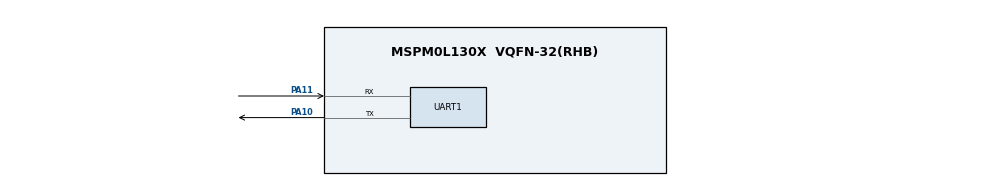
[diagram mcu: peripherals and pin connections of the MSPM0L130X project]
/**
 * These arguments were used when this file was generated. They will be automatically applied on subsequent loads
 * via the GUI or CLI. Run CLI with '--help' for additional information on how to override these arguments.
 * @cliArgs --device "MSPM0L130X" --package "VQFN-32(RHB)" --part "Default" --product "mspm0_sdk@1.20.01.06"
 * @versions {"tool":"1.18.1+3343"}
 */

/**
 * Import the modules used in this configuration.
 */
const Board  = scripting.addModule("/ti/driverlib/Board");
const GPIO   = scripting.addModule("/ti/driverlib/GPIO", {}, false);
const GPIO1  = GPIO.addInstance();
const GPIO2  = GPIO.addInstance();
const GPIO3  = GPIO.addInstance();
const GPIO4  = GPIO.addInstance();
const SYSCTL = scripting.addModule("/ti/driverlib/SYSCTL");
const TIMER  = scripting.addModule("/ti/driverlib/TIMER", {}, false);
const TIMER1 = TIMER.addInstance();
const TIMER2 = TIMER.addInstance();
const UART   = scripting.addModule("/ti/driverlib/UART", {}, false);
const UART1  = UART.addInstance();

/**
 * Write custom configuration values to the imported modules.
 */

GPIO1.$name                          = "GPIO_GRP_0";
GPIO1.associatedPins.create(5);
GPIO1.associatedPins[0].$name        = "CS";
GPIO1.associatedPins[0].assignedPort = "PORTA";
GPIO1.associatedPins[0].initialValue = "SET";
GPIO1.associatedPins[0].ioStructure  = "SD";
GPIO1.associatedPins[0].assignedPin  = "2";
GPIO1.associatedPins[1].$name        = "LED";
GPIO1.associatedPins[1].assignedPort = "PORTA";
GPIO1.associatedPins[1].assignedPin  = "3";
GPIO1.associatedPins[2].assignedPin  = "6";
GPIO1.associatedPins[2].$name        = "D0";
GPIO1.associatedPins[3].$name        = "D1";
GPIO1.associatedPins[3].assignedPin  = "5";
GPIO1.associatedPins[4].$name        = "DC";
GPIO1.associatedPins[4].assignedPin  = "4";

GPIO2.$name                         = "MATRIX";
GPIO2.associatedPins.create(8);
GPIO2.associatedPins[0].$name       = "V1";
GPIO2.associatedPins[0].assignedPin = "13";
GPIO2.associatedPins[1].$name       = "V2";
GPIO2.associatedPins[1].assignedPin = "14";
GPIO2.associatedPins[2].$name       = "V3";
GPIO2.associatedPins[2].assignedPin = "17";
GPIO2.associatedPins[3].$name       = "V4";
GPIO2.associatedPins[3].assignedPin = "18";
GPIO2.associatedPins[4].$name       = "H1";
GPIO2.associatedPins[4].direction   = "INPUT";
GPIO2.associatedPins[4].assignedPin = "0";
GPIO2.associatedPins[4].interruptEn = true;
GPIO2.associatedPins[4].polarity    = "FALL";
GPIO2.associatedPins[5].$name       = "H2";
GPIO2.associatedPins[5].direction   = "INPUT";
GPIO2.associatedPins[5].assignedPin = "1";
GPIO2.associatedPins[5].interruptEn = true;
GPIO2.associatedPins[5].polarity    = "FALL";
GPIO2.associatedPins[6].$name       = "H3";
GPIO2.associatedPins[6].direction   = "INPUT";
GPIO2.associatedPins[6].assignedPin = "7";
GPIO2.associatedPins[6].interruptEn = true;
GPIO2.associatedPins[6].polarity    = "FALL";
GPIO2.associatedPins[7].$name       = "H4";
GPIO2.associatedPins[7].direction   = "INPUT";
GPIO2.associatedPins[7].assignedPin = "12";
GPIO2.associatedPins[7].interruptEn = true;
GPIO2.associatedPins[7].polarity    = "FALL";

GPIO3.$name                          = "BUZZER";
GPIO3.associatedPins.create(2);
GPIO3.associatedPins[0].assignedPin  = "16";
GPIO3.associatedPins[0].$name        = "SDA";
GPIO3.associatedPins[0].initialValue = "SET";
GPIO3.associatedPins[1].assignedPin  = "15";
GPIO3.associatedPins[1].$name        = "SCL";

GPIO4.$name                         = "BLUETOOTH";
GPIO4.associatedPins.create(2);
GPIO4.associatedPins[0].$name       = "TX";
GPIO4.associatedPins[0].assignedPin = "8";
GPIO4.associatedPins[1].$name       = "RX";
GPIO4.associatedPins[1].direction   = "INPUT";
GPIO4.associatedPins[1].assignedPin = "9";

SYSCTL.MFCLKEn = true;

TIMER1.$name             = "TIMER_0";
TIMER1.timerPeriod       = "1 s";
TIMER1.timerClkSrc       = "LFCLK";
TIMER1.timerMode         = "PERIODIC";
TIMER1.interrupts        = ["ZERO"];
TIMER1.interruptPriority = "0";
TIMER1.timerStartTimer   = true;
TIMER1.crossTriggerEn    = true;

TIMER2.$name             = "TIMER_1";
TIMER2.timerClkSrc       = "LFCLK";
TIMER2.timerMode         = "PERIODIC";
TIMER2.interrupts        = ["ZERO"];
TIMER2.interruptPriority = "0";
TIMER2.timerPeriod       = "1 s";
TIMER2.crossTriggerEn    = true;

UART1.$name                    = "UART_0";
UART1.enabledInterrupts        = ["RX","RX_TIMEOUT_ERROR"];
UART1.targetBaudRate           = 115200;
UART1.peripheral.rxPin.$assign = "PA11";
UART1.peripheral.txPin.$assign = "PA10";
UART1.txPinConfig.$name        = "ti_driverlib_gpio_GPIOPinGeneric0";
UART1.rxPinConfig.$name        = "ti_driverlib_gpio_GPIOPinGeneric1";

/**
 * Pinmux solution for unlocked pins/peripherals. This ensures that minor changes to the automatic solver in a future
 * version of the tool will not impact the pinmux you originally saw.  These lines can be completely deleted in order to
 * re-solve from scratch.
 */
Board.peripheral.$suggestSolution            = "DEBUGSS";
Board.peripheral.swclkPin.$suggestSolution   = "PA20";
Board.peripheral.swdioPin.$suggestSolution   = "PA19";
GPIO1.associatedPins[0].pin.$suggestSolution = "PA2";
GPIO1.associatedPins[1].pin.$suggestSolution = "PA3";
GPIO1.associatedPins[2].pin.$suggestSolution = "PA6";
GPIO1.associatedPins[3].pin.$suggestSolution = "PA5";
GPIO1.associatedPins[4].pin.$suggestSolution = "PA4";
GPIO2.associatedPins[0].pin.$suggestSolution = "PA13";
GPIO2.associatedPins[1].pin.$suggestSolution = "PA14";
GPIO2.associatedPins[2].pin.$suggestSolution = "PA17/OPA1.IN0-";
GPIO2.associatedPins[3].pin.$suggestSolution = "PA18";
GPIO2.associatedPins[4].pin.$suggestSolution = "PA0";
GPIO2.associatedPins[5].pin.$suggestSolution = "PA1";
GPIO2.associatedPins[6].pin.$suggestSolution = "PA7";
GPIO2.associatedPins[7].pin.$suggestSolution = "PA12";
GPIO3.associatedPins[0].pin.$suggestSolution = "PA16";
GPIO3.associatedPins[1].pin.$suggestSolution = "PA15";
GPIO4.associatedPins[0].pin.$suggestSolution = "PA8";
GPIO4.associatedPins[1].pin.$suggestSolution = "PA9";
SYSCTL.peripheral.$suggestSolution           = "SYSCTL";
TIMER1.peripheral.$suggestSolution           = "TIMG1";
TIMER2.peripheral.$suggestSolution           = "TIMG0";
UART1.peripheral.$suggestSolution            = "UART1";
